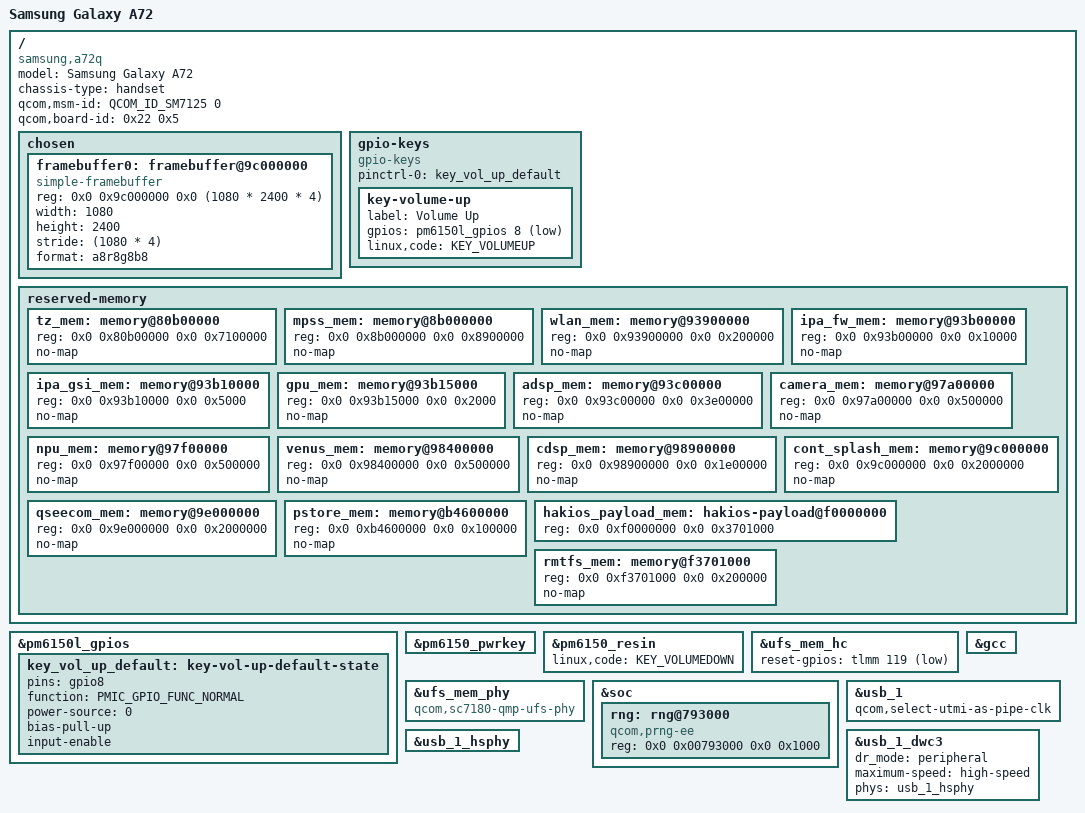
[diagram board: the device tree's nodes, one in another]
// SPDX-License-Identifier: BSD-3-Clause
/*
 * The Samsung Galaxy A72 (a72q, SM-A725F, SM7125) for HakiOS's U-Boot. UNTESTED.
 *
 * Only what U-Boot needs: reserved memory, the framebuffer as the bootloader left it, the keys, USB as a device
 * (fastboot) and UFS. The carve-outs, msm-id and board-id are from the sm7125 mainline tree's a72q device tree
 * (github.com/map220v/sm7125-mainline, a72q-6.10). The framebuffer address is the SM7125 family's usual
 * continuous-splash address (0x9C000000, as on the Xiaomi SM7125 phones) and is NOT verified on the A72: if the
 * screen stays black, U-Boot still runs and its fastboot still answers over USB.
 */

/dts-v1/;

#include <dt-bindings/arm/qcom,ids.h>
#include <dt-bindings/gpio/gpio.h>
#include <dt-bindings/input/linux-event-codes.h>
#include <dt-bindings/pinctrl/qcom,pmic-gpio.h>
#include "sm7125.dtsi"
#include "pm6150.dtsi"
#include "pm6150l.dtsi"

/delete-node/ &rmtfs_mem;
/delete-node/ &ipa_fw_mem;
/delete-node/ &tz_mem;

/ {
	model = "Samsung Galaxy A72";
	compatible = "samsung,a72q", "qcom,sm7125";
	chassis-type = "handset";

	/* what ABL matches against */
	qcom,msm-id = <QCOM_ID_SM7125 0>;
	qcom,board-id = <0x22 0x5>;

	chosen {
		#address-cells = <2>;
		#size-cells = <2>;
		ranges;

		framebuffer0: framebuffer@9c000000 {
			compatible = "simple-framebuffer";
			reg = <0x0 0x9c000000 0x0 (1080 * 2400 * 4)>;
			width = <1080>;
			height = <2400>;
			stride = <(1080 * 4)>;
			format = "a8r8g8b8";
		};
	};

	gpio-keys {
		compatible = "gpio-keys";

		pinctrl-0 = <&key_vol_up_default>;
		pinctrl-names = "default";

		key-volume-up {
			label = "Volume Up";
			gpios = <&pm6150l_gpios 8 GPIO_ACTIVE_LOW>;
			linux,code = <KEY_VOLUMEUP>;
		};
	};

	reserved-memory {
		tz_mem: memory@80b00000 { reg = <0x0 0x80b00000 0x0 0x7100000>; no-map; };
		mpss_mem: memory@8b000000 { reg = <0x0 0x8b000000 0x0 0x8900000>; no-map; };
		wlan_mem: memory@93900000 { reg = <0x0 0x93900000 0x0 0x200000>; no-map; };
		ipa_fw_mem: memory@93b00000 { reg = <0x0 0x93b00000 0x0 0x10000>; no-map; };
		ipa_gsi_mem: memory@93b10000 { reg = <0x0 0x93b10000 0x0 0x5000>; no-map; };
		gpu_mem: memory@93b15000 { reg = <0x0 0x93b15000 0x0 0x2000>; no-map; };
		adsp_mem: memory@93c00000 { reg = <0x0 0x93c00000 0x0 0x3e00000>; no-map; };
		camera_mem: memory@97a00000 { reg = <0x0 0x97a00000 0x0 0x500000>; no-map; };
		npu_mem: memory@97f00000 { reg = <0x0 0x97f00000 0x0 0x500000>; no-map; };
		venus_mem: memory@98400000 { reg = <0x0 0x98400000 0x0 0x500000>; no-map; };
		cdsp_mem: memory@98900000 { reg = <0x0 0x98900000 0x0 0x1e00000>; no-map; };
		cont_splash_mem: memory@9c000000 { reg = <0x0 0x9c000000 0x0 0x2000000>; no-map; };
		qseecom_mem: memory@9e000000 { reg = <0x0 0x9e000000 0x0 0x2000000>; no-map; };
		pstore_mem: memory@b4600000 { reg = <0x0 0xb4600000 0x0 0x100000>; no-map; };

		/*
		 * The HakiOS loader's payload area starts at 0xF0000000, but the modem's rmtfs sits at 0xF3701000 on this
		 * phone: only the 55 MiB below it are given to the payload, so a payload must stay under that.
		 */
		hakios_payload_mem: hakios-payload@f0000000 { reg = <0x0 0xf0000000 0x0 0x3701000>; };
		rmtfs_mem: memory@f3701000 { reg = <0x0 0xf3701000 0x0 0x200000>; no-map; };
	};
};

&pm6150l_gpios {
	key_vol_up_default: key-vol-up-default-state {
		pins = "gpio8";
		function = PMIC_GPIO_FUNC_NORMAL;
		power-source = <0>;
		bias-pull-up;
		input-enable;
	};
};

&pm6150_pwrkey {
	status = "okay";
};

&pm6150_resin {
	linux,code = <KEY_VOLUMEDOWN>;
	status = "okay";
};

&ufs_mem_hc {
	/*
	 * clocks, resets and power-domains stay as sc7180.dtsi has them (&gcc, now driven by clock-sc7180.c).
	 * U-Boot has no SC7180 interconnect provider and ABL already votes the UFS bandwidth: drop the paths.
	 */
	/delete-property/ interconnects;
	/delete-property/ interconnect-names;
	/* UFS_RESET is the SoC's own pad, pin 119 of the TLMM (south tile, 0x7f000) */
	reset-gpios = <&tlmm 119 GPIO_ACTIVE_LOW>;
	status = "okay";
};

&ufs_mem_phy {
	/* Linux binds sc7180 to the sm7150 tables; the fallback lets any U-Boot find it */
	compatible = "qcom,sc7180-qmp-ufs-phy", "qcom,sm7150-qmp-ufs-phy";
	status = "okay";
};

/* gcc's own vote on RPMh CX (SC7180_CX = 0) has no table in U-Boot: ABL keeps CX on */
&gcc {
	/delete-property/ power-domains;
};

/* USB 2.0 as a device: U-Boot's fastboot */
/* the PRNG for UEFI's EFI_RNG_PROTOCOL (sc7180.dtsi has no node for it); ABL keeps its clock on */
&soc {
	rng: rng@793000 {
		compatible = "qcom,prng-ee";
		reg = <0x0 0x00793000 0x0 0x1000>;
	};
};

&usb_1 {
	qcom,select-utmi-as-pipe-clk;
	status = "okay";
};

&usb_1_dwc3 {
	dr_mode = "peripheral";
	maximum-speed = "high-speed";
	phys = <&usb_1_hsphy>;
	phy-names = "usb2-phy";
};

&usb_1_hsphy {
	status = "okay";
};
